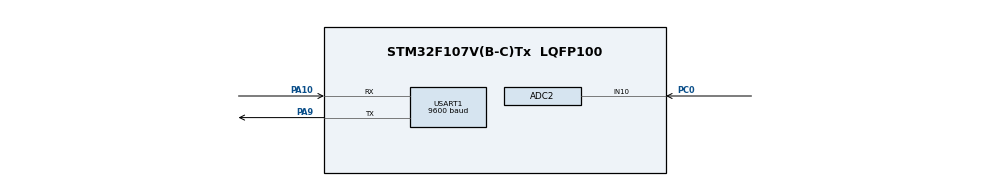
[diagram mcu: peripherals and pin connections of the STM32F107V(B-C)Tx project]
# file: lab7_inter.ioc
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ADC2.Channel-1\#ChannelRegularConversion=ADC_CHANNEL_10
ADC2.NbrOfConversionFlag=1
ADC2.Rank-1\#ChannelRegularConversion=1
ADC2.SamplingTime-1\#ChannelRegularConversion=ADC_SAMPLETIME_1CYCLE_5
Mcu.Family=STM32F1
Mcu.Name=STM32F107V(B-C)Tx
Mcu.Package=LQFP100
NVIC.PriorityGroup=NVIC_PRIORITYGROUP_4
NVIC.USART1_IRQn=true\:0\:0\:false\:false\:true\:true\:true
OSC_IN.Mode=HSE-External-Oscillator
OSC_IN.Signal=RCC_OSC_IN
OSC_OUT.Mode=HSE-External-Oscillator
OSC_OUT.Signal=RCC_OSC_OUT
PA10.Mode=Asynchronous
PA10.Signal=USART1_RX
PA13.Mode=Serial_Wire
PA13.Signal=SYS_JTMS-SWDIO
PA14.Mode=Serial_Wire
PA14.Signal=SYS_JTCK-SWCLK
PA9.Mode=Asynchronous
PA9.Signal=USART1_TX
PC0.Signal=ADCx_IN10
ProjectManager.HeapSize=0x200
ProjectManager.StackSize=0x400
ProjectManager.TargetToolchain=MDK-ARM V5.32
RCC.USBFreq_Value=10666666.666666666
SH.ADCx_IN10.0=ADC2_IN10,IN10
USART1.BaudRate=9600
USART1.VirtualMode=VM_ASYNC
board=custom

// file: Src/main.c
/* USER CODE BEGIN Header */
/**
  ******************************************************************************
  * @file           : main.c
  * @brief          : Main program body
  ******************************************************************************
  * @attention
  *
  * Copyright (c) 2022 STMicroelectronics.
  * All rights reserved.
  *
  * This software is licensed under terms that can be found in the LICENSE file
  * in the root directory of this software component.
  * If no LICENSE file comes with this software, it is provided AS-IS.
  *
  ******************************************************************************
  */
/* USER CODE END Header */
#include "main.h"

ADC_HandleTypeDef hadc2;

UART_HandleTypeDef huart1;

/* USER CODE BEGIN PV */
uint8_t data_receive[1]={'A'};

/* USER CODE END PV */

void SystemClock_Config(void);
static void MX_GPIO_Init(void);
static void MX_USART1_UART_Init(void);
static void MX_ADC2_Init(void);

/* USER CODE BEGIN 0 */
const LM35_CfgType LM35_CfgParam[SENSORS_NUM] =
{
    // LM35 Sensor 1 Configurations
    {
    GPIOA,
    ADC1,
    ADC_CHANNEL_5
    }
};
/* USER CODE END 0 */

int main(void)
{

  /* MCU Configuration--------------------------------------------------------*/

  /* Reset of all peripherals, Initializes the Flash interface and the Systick. */
  HAL_Init();

  /* Configure the system clock */
  SystemClock_Config();

  /* Initialize all configured peripherals */
  MX_GPIO_Init();
  MX_USART1_UART_Init();
  MX_ADC2_Init();

  /* Infinite loop */
  /* USER CODE BEGIN WHILE */
	 float Temp = 0;
    uint8_t MSG[16] = {0};

    HAL_Init();
    SystemClock_Config();
    MX_GPIO_Init();
    LCD_Init();
    LCD_Clear();
    LCD_Set_Cursor(1, 1);
    LCD_Write_String("Temperature Is:");
    LM35_Init(0);

    while (1)
    {
        Temp = LM35_Read(0);
        sprintf(MSG, "%.3f C", Temp);
        LCD_Set_Cursor(2, 1);
        LCD_Write_String(MSG);
        HAL_Delay(100);

    /* USER CODE END WHILE */

  }
}

void SystemClock_Config(void)
{
  RCC_OscInitTypeDef RCC_OscInitStruct = {0};
  RCC_ClkInitTypeDef RCC_ClkInitStruct = {0};
  RCC_PeriphCLKInitTypeDef PeriphClkInit = {0};

  /** Initializes the RCC Oscillators according to the specified parameters
  * in the RCC_OscInitTypeDef structure.
  */
  RCC_OscInitStruct.OscillatorType = RCC_OSCILLATORTYPE_HSI;
  RCC_OscInitStruct.HSIState = RCC_HSI_ON;
  RCC_OscInitStruct.HSICalibrationValue = RCC_HSICALIBRATION_DEFAULT;
  RCC_OscInitStruct.PLL.PLLState = RCC_PLL_NONE;
  RCC_OscInitStruct.PLL2.PLL2State = RCC_PLL_NONE;
  if (HAL_RCC_OscConfig(&RCC_OscInitStruct) != HAL_OK)
  {
    Error_Handler();
  }
  /** Initializes the CPU, AHB and APB buses clocks
  */
  RCC_ClkInitStruct.ClockType = RCC_CLOCKTYPE_HCLK|RCC_CLOCKTYPE_SYSCLK
                              |RCC_CLOCKTYPE_PCLK1|RCC_CLOCKTYPE_PCLK2;
  RCC_ClkInitStruct.SYSCLKSource = RCC_SYSCLKSOURCE_HSI;
  RCC_ClkInitStruct.AHBCLKDivider = RCC_SYSCLK_DIV1;
  RCC_ClkInitStruct.APB1CLKDivider = RCC_HCLK_DIV1;
  RCC_ClkInitStruct.APB2CLKDivider = RCC_HCLK_DIV1;

  if (HAL_RCC_ClockConfig(&RCC_ClkInitStruct, FLASH_LATENCY_0) != HAL_OK)
  {
    Error_Handler();
  }
  PeriphClkInit.PeriphClockSelection = RCC_PERIPHCLK_ADC;
  PeriphClkInit.AdcClockSelection = RCC_ADCPCLK2_DIV2;
  if (HAL_RCCEx_PeriphCLKConfig(&PeriphClkInit) != HAL_OK)
  {
    Error_Handler();
  }
  /** Configure the Systick interrupt time
  */
  __HAL_RCC_PLLI2S_ENABLE();
}

static void MX_ADC2_Init(void)
{

  ADC_ChannelConfTypeDef sConfig = {0};

  /** Common config
  */
  hadc2.Instance = ADC2;
  hadc2.Init.ScanConvMode = ADC_SCAN_DISABLE;
  hadc2.Init.ContinuousConvMode = DISABLE;
  hadc2.Init.DiscontinuousConvMode = DISABLE;
  hadc2.Init.ExternalTrigConv = ADC_SOFTWARE_START;
  hadc2.Init.DataAlign = ADC_DATAALIGN_RIGHT;
  hadc2.Init.NbrOfConversion = 1;
  if (HAL_ADC_Init(&hadc2) != HAL_OK)
  {
    Error_Handler();
  }
  /** Configure Regular Channel
  */
  sConfig.Channel = ADC_CHANNEL_10;
  sConfig.Rank = ADC_REGULAR_RANK_1;
  sConfig.SamplingTime = ADC_SAMPLETIME_1CYCLE_5;
  if (HAL_ADC_ConfigChannel(&hadc2, &sConfig) != HAL_OK)
  {
    Error_Handler();
  }

}

static void MX_USART1_UART_Init(void)
{

  huart1.Instance = USART1;
  huart1.Init.BaudRate = 9600;
  huart1.Init.WordLength = UART_WORDLENGTH_8B;
  huart1.Init.StopBits = UART_STOPBITS_1;
  huart1.Init.Parity = UART_PARITY_NONE;
  huart1.Init.Mode = UART_MODE_TX_RX;
  huart1.Init.HwFlowCtl = UART_HWCONTROL_NONE;
  huart1.Init.OverSampling = UART_OVERSAMPLING_16;
  if (HAL_UART_Init(&huart1) != HAL_OK)
  {
    Error_Handler();
  }

}

static void MX_GPIO_Init(void)
{

  /* GPIO Ports Clock Enable */
  __HAL_RCC_GPIOC_CLK_ENABLE();
  __HAL_RCC_GPIOA_CLK_ENABLE();

}

void Error_Handler(void)
{
  __disable_irq();
  while (1)
  {
  }
}
